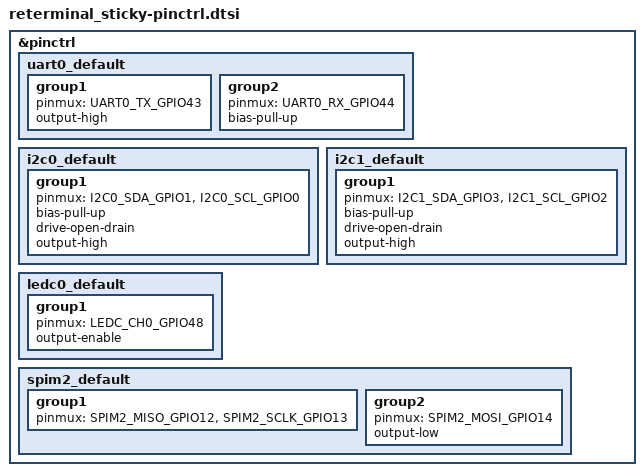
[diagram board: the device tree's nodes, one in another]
/*
 * SPDX-FileCopyrightText: Copyright The Zephyr Project Contributors
 * SPDX-License-Identifier: Apache-2.0
 */

#include <zephyr/dt-bindings/pinctrl/esp32s3-pinctrl.h>

&pinctrl {
	uart0_default: uart0_default {
		group1 {
			pinmux = <UART0_TX_GPIO43>;
			output-high;
		};

		group2 {
			pinmux = <UART0_RX_GPIO44>;
			bias-pull-up;
		};
	};

	i2c0_default: i2c0_default {
		group1 {
			pinmux = <I2C0_SDA_GPIO1>,
				 <I2C0_SCL_GPIO0>;
			bias-pull-up;
			drive-open-drain;
			output-high;
		};
	};

	i2c1_default: i2c1_default {
		group1 {
			pinmux = <I2C1_SDA_GPIO3>,
				 <I2C1_SCL_GPIO2>;
			bias-pull-up;
			drive-open-drain;
			output-high;
		};
	};

	ledc0_default: ledc0_default {
		group1 {
			pinmux = <LEDC_CH0_GPIO48>;
			output-enable;
		};
	};

	spim2_default: spim2_default {
		group1 {
			pinmux = <SPIM2_MISO_GPIO12>,
				 <SPIM2_SCLK_GPIO13>;
		};

		group2 {
			pinmux = <SPIM2_MOSI_GPIO14>;
			output-low;
		};
	};
};
